# PADCFG_CTRL0_CFG0 register map
Vendor: Texas Instruments
Peripheral module from a debugger description file (folder am62A).
Registers are 32-bit, access per field, reset 0x8214007 unless marked. A register's access mark holds for its fields unless they carry their own. Offsets are as the file gives them; lines under a group give offsets from that group; [hi:lo] are bit positions; {n}, {i} and the like mark numbered series; 'fields as' and 'values as' point back to an identical list; <NAME> marks a mode.

## PADCFG_CTRL0_CFG0 (part 1 of 2)
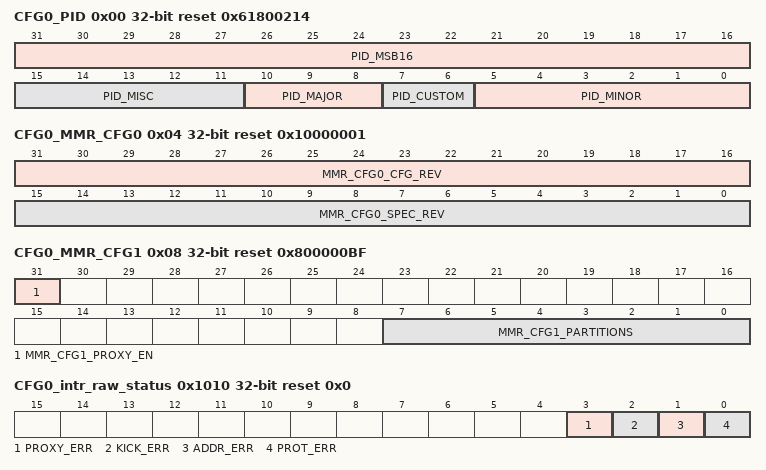
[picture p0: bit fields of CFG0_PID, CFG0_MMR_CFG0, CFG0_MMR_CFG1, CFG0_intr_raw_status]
0x00 CFG0_PID ro reset 0x61800214
  [31:16] PID_MSB16, [15:11] PID_MISC, [10:8] PID_MAJOR, [7:6] PID_CUSTOM, [5:0] PID_MINOR
0x04 CFG0_MMR_CFG0 ro reset 0x10000001
  [31:16] MMR_CFG0_CFG_REV — Major configuration release
  [15:0] MMR_CFG0_SPEC_REV — Minor spec-only revision. Doesn't change RTL release
0x08 CFG0_MMR_CFG1 ro reset 0x800000BF
  [31] MMR_CFG1_PROXY_EN — Proxy addressing enabled
  [7:0] MMR_CFG1_PARTITIONS — Indicates present partitions
0x1008 CFG0_LOCK0_KICK0 rw reset 0x0
  [31:0] LOCK0_KICK0 — - KICK0 component
0x100C CFG0_LOCK0_KICK1 rw reset 0x0
  [31:0] LOCK0_KICK1 — - KICK1 component
0x1010 CFG0_intr_raw_status access not given reset 0x0
  [3] PROXY_ERR — Proxy0 access violation error. Raw status is read. Write a 1 to set the status. Writing a 0 has no effect. (access R/W1TS)
  [2] KICK_ERR — Kick access violation error. Raw status is read. Write a 1 to set the status. Writing a 0 has no effect. (access R/W1TS)
  [1] ADDR_ERR — Addressing violation error. Raw status is read. Write a 1 to set the status. Writing a 0 has no effect. (access R/W1TS)
  [0] PROT_ERR — Protection violation error. Raw status is read. Write a 1 to set the status. Writing a 0 has no effect. (access R/W1TS)
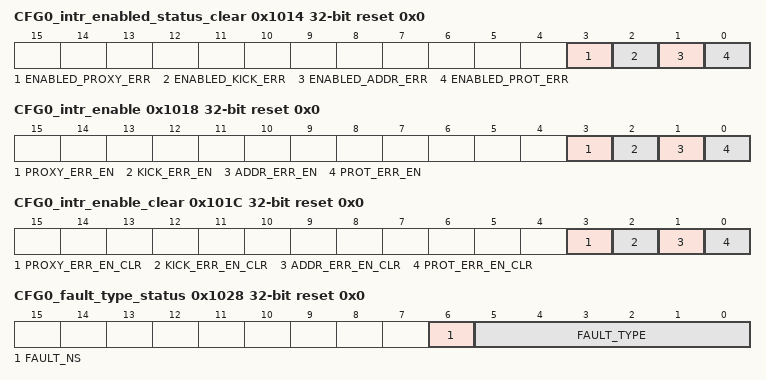
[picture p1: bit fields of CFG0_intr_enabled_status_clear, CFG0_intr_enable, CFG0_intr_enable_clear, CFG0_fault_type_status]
0x1014 CFG0_intr_enabled_status_clear access not given reset 0x0
  [3] ENABLED_PROXY_ERR — Proxy0 access violation error. Enabled status is read. Write a 1 to clear the status. Writing a 0 has no effect. (access R/W1TC)
  [2] ENABLED_KICK_ERR — Kick access violation error. Enabled status is read. Write a 1 to clear the status. Writing a 0 has no effect. (access R/W1TC)
  [1] ENABLED_ADDR_ERR — Addressing violation error. Enabled status is read. Write a 1 to clear the status. Writing a 0 has no effect. (access R/W1TC)
  [0] ENABLED_PROT_ERR — Protection violation error. Enabled status is read. Write a 1 to clear the status. Writing a 0 has no effect. (access R/W1TC)
0x1018 CFG0_intr_enable access not given reset 0x0
  [3] PROXY_ERR_EN — Proxy0 access violation error enable. Write a 1 to set the enable. Writing a 0 has no effect. (access R/W1TS)
  [2] KICK_ERR_EN — Kick access violation error enable. Write a 1 to set the enable. Writing a 0 has no effect. (access R/W1TS)
  [1] ADDR_ERR_EN — Addressing violation error enable. Write a 1 to set the enable. Writing a 0 has no effect. (access R/W1TS)
  [0] PROT_ERR_EN — Protection violation error enable. Write a 1 to set the enable. Writing a 0 has no effect. (access R/W1TS)
0x101C CFG0_intr_enable_clear access not given reset 0x0
  [3] PROXY_ERR_EN_CLR — Proxy0 access violation error enable clear. Write a 1 to clear the enable. Writing a 0 has no effect. (access R/W1TC)
  [2] KICK_ERR_EN_CLR — Kick access violation error enable clear. Write a 1 to clear the enable. Writing a 0 has no effect. (access R/W1TC)
  [1] ADDR_ERR_EN_CLR — Addressing violation error enable clear. Write a 1 to clear the enable. Writing a 0 has no effect. (access R/W1TC)
  [0] PROT_ERR_EN_CLR — Protection violation error enable clear. Write a 1 to clear the enable. Writing a 0 has no effect. (access R/W1TC)
0x1020 CFG0_eoi rw reset 0x0
  [7:0] EOI_VECTOR — EOI vector value. Write this with interrupt distribution value in the chip.
0x1024 CFG0_fault_address ro reset 0x0
  [31:0] FAULT_ADDR — Fault Address.
0x1028 CFG0_fault_type_status ro reset 0x0
  [6] FAULT_NS — Non-secure access.
  [5:0] FAULT_TYPE — Fault Type 10_0000 = Supervisor read fault - priv = 1 dir = 1 dtype != 1 01_0000 = Supervisor write fault - priv = 1 dir = 0 00_1000 = Supervisor execute fault - priv = 1 dir = 1 dtype = 1 00_0100 = User read fault - priv = 0 dir = 1 dtype = 1 00_0010 = User write fault - priv = 0 dir = 0 00_0001 = User execute fault - priv = 0 dir = 1 dtype = 1 00_0000 = No fault
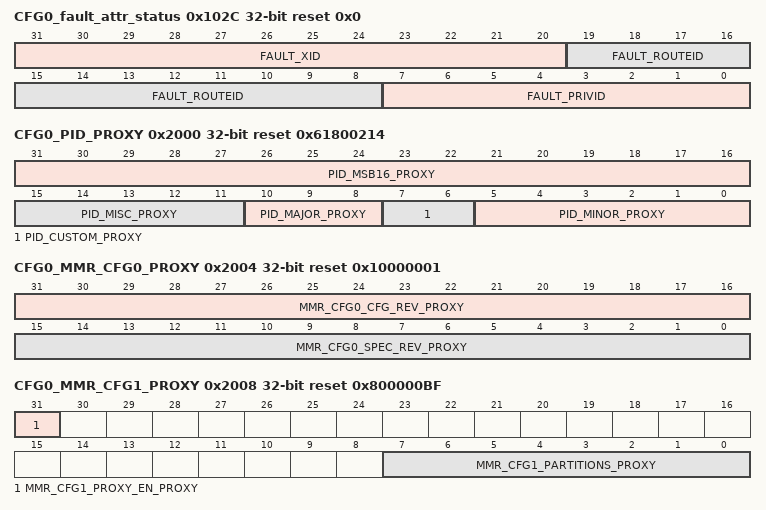
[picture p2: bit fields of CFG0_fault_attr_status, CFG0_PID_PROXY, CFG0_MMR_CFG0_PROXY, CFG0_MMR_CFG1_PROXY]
0x102C CFG0_fault_attr_status ro reset 0x0
  [31:20] FAULT_XID — XID.
  [19:8] FAULT_ROUTEID — Route ID.
  [7:0] FAULT_PRIVID — Privilege ID.
0x1030 CFG0_fault_clear wo reset 0x0
  [0] FAULT_CLR — Fault clear. Writing a 1 clears the current fault. Writing a 0 has no effect.
0x1100 CFG0_CLAIMREG_P0_R0_READONLY ro reset 0x0
  [31:0] CLAIMREG_P0_R0_READONLY — Claim bits for Partition 0
0x2000 CFG0_PID_PROXY ro reset 0x61800214
  [31:16] PID_MSB16_PROXY, [15:11] PID_MISC_PROXY, [10:8] PID_MAJOR_PROXY, [7:6] PID_CUSTOM_PROXY, [5:0] PID_MINOR_PROXY
0x2004 CFG0_MMR_CFG0_PROXY ro reset 0x10000001
  [31:16] MMR_CFG0_CFG_REV_PROXY — Major configuration release
  [15:0] MMR_CFG0_SPEC_REV_PROXY — Minor spec-only revision. Doesn't change RTL release
0x2008 CFG0_MMR_CFG1_PROXY ro reset 0x800000BF
  [31] MMR_CFG1_PROXY_EN_PROXY — Proxy addressing enabled
  [7:0] MMR_CFG1_PARTITIONS_PROXY — Indicates present partitions
0x3008 CFG0_LOCK0_KICK0_PROXY rw reset 0x0
  [31:0] LOCK0_KICK0_PROXY — - KICK0 component
0x300C CFG0_LOCK0_KICK1_PROXY rw reset 0x0
  [31:0] LOCK0_KICK1_PROXY — - KICK1 component
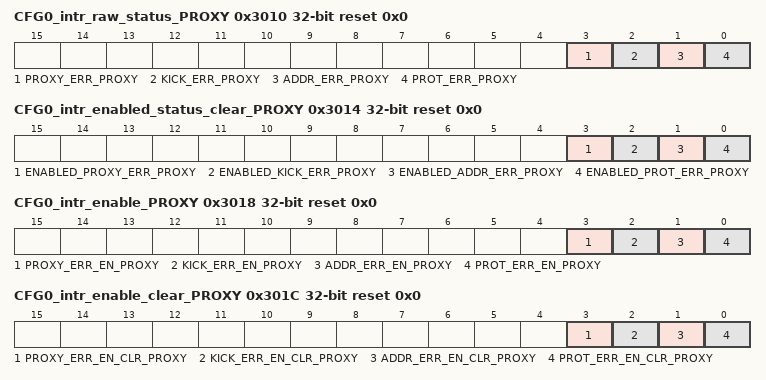
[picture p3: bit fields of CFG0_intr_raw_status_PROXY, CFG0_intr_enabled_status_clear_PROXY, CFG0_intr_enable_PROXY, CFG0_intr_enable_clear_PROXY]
0x3010 CFG0_intr_raw_status_PROXY access not given reset 0x0
  [3] PROXY_ERR_PROXY — Proxy0 access violation error. Raw status is read. Write a 1 to set the status. Writing a 0 has no effect. (access R/W1TS)
  [2] KICK_ERR_PROXY — Kick access violation error. Raw status is read. Write a 1 to set the status. Writing a 0 has no effect. (access R/W1TS)
  [1] ADDR_ERR_PROXY — Addressing violation error. Raw status is read. Write a 1 to set the status. Writing a 0 has no effect. (access R/W1TS)
  [0] PROT_ERR_PROXY — Protection violation error. Raw status is read. Write a 1 to set the status. Writing a 0 has no effect. (access R/W1TS)
0x3014 CFG0_intr_enabled_status_clear_PROXY access not given reset 0x0
  [3] ENABLED_PROXY_ERR_PROXY — Proxy0 access violation error. Enabled status is read. Write a 1 to clear the status. Writing a 0 has no effect. (access R/W1TC)
  [2] ENABLED_KICK_ERR_PROXY — Kick access violation error. Enabled status is read. Write a 1 to clear the status. Writing a 0 has no effect. (access R/W1TC)
  [1] ENABLED_ADDR_ERR_PROXY — Addressing violation error. Enabled status is read. Write a 1 to clear the status. Writing a 0 has no effect. (access R/W1TC)
  [0] ENABLED_PROT_ERR_PROXY — Protection violation error. Enabled status is read. Write a 1 to clear the status. Writing a 0 has no effect. (access R/W1TC)
0x3018 CFG0_intr_enable_PROXY access not given reset 0x0
  [3] PROXY_ERR_EN_PROXY — Proxy0 access violation error enable. Write a 1 to set the enable. Writing a 0 has no effect. (access R/W1TS)
  [2] KICK_ERR_EN_PROXY — Kick access violation error enable. Write a 1 to set the enable. Writing a 0 has no effect. (access R/W1TS)
  [1] ADDR_ERR_EN_PROXY — Addressing violation error enable. Write a 1 to set the enable. Writing a 0 has no effect. (access R/W1TS)
  [0] PROT_ERR_EN_PROXY — Protection violation error enable. Write a 1 to set the enable. Writing a 0 has no effect. (access R/W1TS)
0x301C CFG0_intr_enable_clear_PROXY access not given reset 0x0
  [3] PROXY_ERR_EN_CLR_PROXY — Proxy0 access violation error enable clear. Write a 1 to clear the enable. Writing a 0 has no effect. (access R/W1TC)
  [2] KICK_ERR_EN_CLR_PROXY — Kick access violation error enable clear. Write a 1 to clear the enable. Writing a 0 has no effect. (access R/W1TC)
  [1] ADDR_ERR_EN_CLR_PROXY — Addressing violation error enable clear. Write a 1 to clear the enable. Writing a 0 has no effect. (access R/W1TC)
  [0] PROT_ERR_EN_CLR_PROXY — Protection violation error enable clear. Write a 1 to clear the enable. Writing a 0 has no effect. (access R/W1TC)
0x3020 CFG0_eoi_PROXY rw reset 0x0
  [7:0] EOI_VECTOR_PROXY — EOI vector value. Write this with interrupt distribution value in the chip.
0x3024 CFG0_fault_address_PROXY ro reset 0x0
  [31:0] FAULT_ADDR_PROXY — Fault Address.
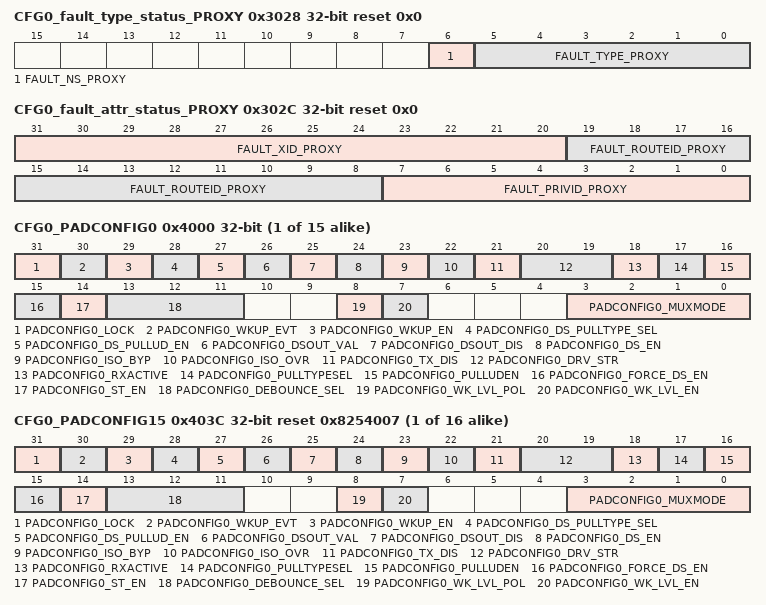
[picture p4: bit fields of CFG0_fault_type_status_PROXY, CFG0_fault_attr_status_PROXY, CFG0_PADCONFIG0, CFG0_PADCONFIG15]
0x3028 CFG0_fault_type_status_PROXY ro reset 0x0
  [6] FAULT_NS_PROXY — Non-secure access.
  [5:0] FAULT_TYPE_PROXY — Fault Type 10_0000 = Supervisor read fault - priv = 1 dir = 1 dtype != 1 01_0000 = Supervisor write fault - priv = 1 dir = 0 00_1000 = Supervisor execute fault - priv = 1 dir = 1 dtype = 1 00_0100 = User read fault - priv = 0 dir = 1 dtype = 1 00_0010 = User write fault - priv = 0 dir = 0 00_0001 = User execute fault - priv = 0 dir = 1 dtype = 1 00_0000 = No fault
0x302C CFG0_fault_attr_status_PROXY ro reset 0x0
  [31:20] FAULT_XID_PROXY — XID.
  [19:8] FAULT_ROUTEID_PROXY — Route ID.
  [7:0] FAULT_PRIVID_PROXY — Privilege ID.
0x3030 CFG0_fault_clear_PROXY wo reset 0x0
  [0] FAULT_CLR_PROXY — Fault clear. Writing a 1 clears the current fault. Writing a 0 has no effect.
0x3100 CFG0_CLAIMREG_P0_R0 rw reset 0x0
  [31:0] CLAIMREG_P0_R0 — Claim bits for Partition 0
{0x4000+4i} CFG0_PADCONFIG{i} (i=0..14)
  [31] PADCONFIG{i}_LOCK rw — Lock 0 - Padconfig register is unlocked 1 - Padconfig register is locked from further writes
  [30] PADCONFIG{i}_WKUP_EVT ro — Wakeup event status 0 - No wake event on pin 1 - Wake event occurred on pin
  [29] PADCONFIG{i}_WKUP_EN rw — Wakeup enable 0 - Wakeup operation disabled 1 - Wakeup operation enabled
  [28] PADCONFIG{i}_DS_PULLTYPE_SEL rw — Deep Sleep pull-up/down selection 0 - Offmode pulldown selected 1 - Offmode pullup selected
  [27] PADCONFIG{i}_DS_PULLUD_EN rw — Deep Sleep pull-up/down enable (active low) 0 - Pullup / pulldown is enabled 1 - Pullup / pulldown is disabled
  [26] PADCONFIG{i}_DSOUT_VAL rw — Deep Sleep output value 0 - Output value is 0 1 - Output value is 1
  [25] PADCONFIG{i}_DSOUT_DIS rw — Deep Sleep output disable 0 - Output enabled 1 - Output disabled
  [24] PADCONFIG{i}_DS_EN rw — Deep Sleep override control 0 - IO keeps its previous state when Deep Sleep mode is active 1 - IO state is forced to OFF mode value when Deep Sleep mode is active
  [23] PADCONFIG{i}_ISO_BYP rw — Isolation Bypass 0 - IO isolation is preserved 1 - IO isolation is bypassed
  [22] PADCONFIG{i}_ISO_OVR rw — Isolation Override 0 - IO isolation is preserved 1 - IO isolation is overridden
  [21] PADCONFIG{i}_TX_DIS rw — Driver Disable 0 - Driver is enabled 1 - Driver is disabled
  [20:19] PADCONFIG{i}_DRV_STR rw — Drive Strength Control . Selects the drive strength value for LVCMOS pins. (Does not apply to other pin types)
  [18] PADCONFIG{i}_RXACTIVE rw — Input enable for the Pad 0 - Receiver disabled 1 - Receiver enabled
  [17] PADCONFIG{i}_PULLTYPESEL rw — Pad Pullup / Pulldown type selection 0 - Pulldown selected 1 - Pullup selected
  [16] PADCONFIG{i}_PULLUDEN rw — Pad Pullup / Pulldown enable. This is an active low signal. 0 - Pullup / Pulldown enabled 1 - Pullup / Pulldown disabled
  [15] PADCONFIG{i}_FORCE_DS_EN rw — Enable pad Deep Sleep controls by overriding WKUP DM gating 0 - Deep Sleep pad controls are gated by the WKUP DM 1 - Activate Deep Sleep pad controls (override WKUP DM gating logic)
  [14] PADCONFIG{i}_ST_EN rw — Receiver Schmitt Trigger enable 0 - Schmitt trigger input disabled 1 - Schmitt trigger input enabled
  [13:11] PADCONFIG{i}_DEBOUNCE_SEL rw — Selects the debouce period for the pad.
  [8] PADCONFIG{i}_WK_LVL_POL rw — Level Sensitive Wakeup Polarity This bit is not relevant unless wk_lvl_en is set to 1'b1. 0 - Low. A low (0) value on the pin causes a wakeup 1 - High. A high (1) value on the pin causes a wakeup
  [7] PADCONFIG{i}_WK_LVL_EN rw — Level Sensitive Wakeup Enable 0 - Disabled. Wakeup is triggered by change of the pin input value 1 - Enabled. Wakeup is triggered when the pin matches the value specified by wk_lvl_pol. The chosen polarity must be maintained. (e.g. until wakeup completion is confirmed)
  [3:0] PADCONFIG{i}_MUXMODE rw — Pad functional signal mux selection Field values (others are reserved): 4'b0000 - Mux Mode 0 4'b0001 - Mux Mode 1 4'b0010 - Mux Mode 2 4'b0011 - Mux Mode 3 4'b0100 - Mux Mode 4 4'b0101 - Mux Mode 5 4'b0110 - Mux Mode 6 4'b0111 - Mux Mode 7 4'b1000 - Mux Mode 8 4'b1001 - Mux Mode 9 4'b1010 - Mux Mode 10 4'b1011 - Mux Mode 11 4'b1100 - Mux Mode 12 4'b1101 - Mux Mode 13 4'b1110 - Mux Mode 14 4'b1111 - Mux Mode 15
{0x4000+4i} CFG0_PADCONFIG{i} reset 0x8254007 (i=15..30)
  fields as CFG0_PADCONFIG0
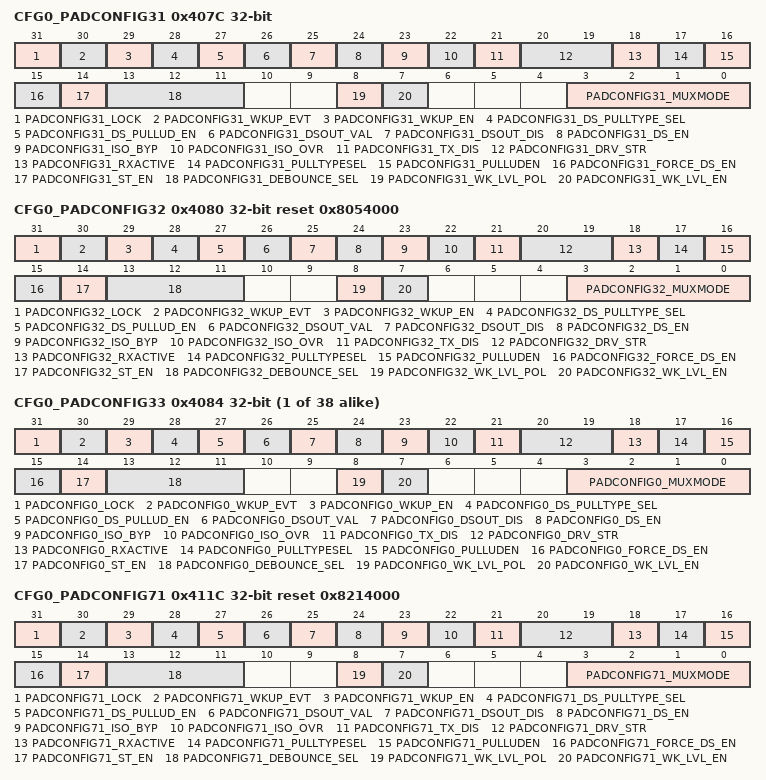
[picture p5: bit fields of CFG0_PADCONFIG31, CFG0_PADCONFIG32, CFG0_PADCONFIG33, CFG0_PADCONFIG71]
0x407C CFG0_PADCONFIG31
  [31] PADCONFIG31_LOCK rw — Lock 0 - Padconfig register is unlocked 1 - Padconfig register is locked from further writes
  [30] PADCONFIG31_WKUP_EVT ro — Wakeup event status 0 - No wake event on pin 1 - Wake event occurred on pin
  [29] PADCONFIG31_WKUP_EN rw — Wakeup enable 0 - Wakeup operation disabled 1 - Wakeup operation enabled
  [28] PADCONFIG31_DS_PULLTYPE_SEL rw — Deep Sleep pull-up/down selection 0 - Offmode pulldown selected 1 - Offmode pullup selected
  [27] PADCONFIG31_DS_PULLUD_EN rw — Deep Sleep pull-up/down enable (active low) 0 - Pullup / pulldown is enabled 1 - Pullup / pulldown is disabled
  [26] PADCONFIG31_DSOUT_VAL rw — Deep Sleep output value 0 - Output value is 0 1 - Output value is 1
  [25] PADCONFIG31_DSOUT_DIS rw — Deep Sleep output disable 0 - Output enabled 1 - Output disabled
  [24] PADCONFIG31_DS_EN rw — Deep Sleep override control 0 - IO keeps its previous state when Deep Sleep mode is active 1 - IO state is forced to OFF mode value when Deep Sleep mode is active
  [23] PADCONFIG31_ISO_BYP rw — Isolation Bypass 0 - IO isolation is preserved 1 - IO isolation is bypassed
  [22] PADCONFIG31_ISO_OVR rw — Isolation Override 0 - IO isolation is preserved 1 - IO isolation is overridden
  [21] PADCONFIG31_TX_DIS rw — Driver Disable 0 - Driver is enabled 1 - Driver is disabled
  [20:19] PADCONFIG31_DRV_STR rw — Drive Strength Control . Selects the drive strength value for LVCMOS pins. (Does not apply to other pin types)
  [18] PADCONFIG31_RXACTIVE rw — Input enable for the Pad 0 - Receiver disabled 1 - Receiver enabled
  [17] PADCONFIG31_PULLTYPESEL rw — Pad Pullup / Pulldown type selection 0 - Pulldown selected 1 - Pullup selected
  [16] PADCONFIG31_PULLUDEN rw — Pad Pullup / Pulldown enable. This is an active low signal. 0 - Pullup / Pulldown enabled 1 - Pullup / Pulldown disabled
  [15] PADCONFIG31_FORCE_DS_EN rw — Enable pad Deep Sleep controls by overriding WKUP DM gating 0 - Deep Sleep pad controls are gated by the WKUP DM 1 - Activate Deep Sleep pad controls (override WKUP DM gating logic)
  [14] PADCONFIG31_ST_EN rw — Receiver Schmitt Trigger enable 0 - Schmitt trigger input disabled 1 - Schmitt trigger input enabled
  [13:11] PADCONFIG31_DEBOUNCE_SEL rw — Selects the debouce period for the pad.
  [8] PADCONFIG31_WK_LVL_POL rw — Level Sensitive Wakeup Polarity This bit is not relevant unless wk_lvl_en is set to 1'b1. 0 - Low. A low (0) value on the pin causes a wakeup 1 - High. A high (1) value on the pin causes a wakeup
  [7] PADCONFIG31_WK_LVL_EN rw — Level Sensitive Wakeup Enable 0 - Disabled. Wakeup is triggered by change of the pin input value 1 - Enabled. Wakeup is triggered when the pin matches the value specified by wk_lvl_pol. The chosen polarity must be maintained. (e.g. until wakeup completion is confirmed)
  [3:0] PADCONFIG31_MUXMODE rw — Pad functional signal mux selection Field values (others are reserved): 4'b0000 - Mux Mode 0 4'b0001 - Mux Mode 1 4'b0010 - Mux Mode 2 4'b0011 - Mux Mode 3 4'b0100 - Mux Mode 4 4'b0101 - Mux Mode 5 4'b0110 - Mux Mode 6 4'b0111 - Mux Mode 7 4'b1000 - Mux Mode 8 4'b1001 - Mux Mode 9 4'b1010 - Mux Mode 10 4'b1011 - Mux Mode 11 4'b1100 - Mux Mode 12 4'b1101 - Mux Mode 13 4'b1110 - Mux Mode 14 4'b1111 - Mux Mode 15
0x4080 CFG0_PADCONFIG32 reset 0x8054000
  [31] PADCONFIG32_LOCK rw — Lock 0 - Padconfig register is unlocked 1 - Padconfig register is locked from further writes
  [30] PADCONFIG32_WKUP_EVT ro — Wakeup event status 0 - No wake event on pin 1 - Wake event occurred on pin
  [29] PADCONFIG32_WKUP_EN rw — Wakeup enable 0 - Wakeup operation disabled 1 - Wakeup operation enabled
  [28] PADCONFIG32_DS_PULLTYPE_SEL rw — Deep Sleep pull-up/down selection 0 - Offmode pulldown selected 1 - Offmode pullup selected
  [27] PADCONFIG32_DS_PULLUD_EN rw — Deep Sleep pull-up/down enable (active low) 0 - Pullup / pulldown is enabled 1 - Pullup / pulldown is disabled
  [26] PADCONFIG32_DSOUT_VAL rw — Deep Sleep output value 0 - Output value is 0 1 - Output value is 1
  [25] PADCONFIG32_DSOUT_DIS rw — Deep Sleep output disable 0 - Output enabled 1 - Output disabled
  [24] PADCONFIG32_DS_EN rw — Deep Sleep override control 0 - IO keeps its previous state when Deep Sleep mode is active 1 - IO state is forced to OFF mode value when Deep Sleep mode is active
  [23] PADCONFIG32_ISO_BYP rw — Isolation Bypass 0 - IO isolation is preserved 1 - IO isolation is bypassed
  [22] PADCONFIG32_ISO_OVR rw — Isolation Override 0 - IO isolation is preserved 1 - IO isolation is overridden
  [21] PADCONFIG32_TX_DIS rw — Driver Disable 0 - Driver is enabled 1 - Driver is disabled
  [20:19] PADCONFIG32_DRV_STR rw — Drive Strength Control . Selects the drive strength value for LVCMOS pins. (Does not apply to other pin types)
  [18] PADCONFIG32_RXACTIVE rw — Input enable for the Pad 0 - Receiver disabled 1 - Receiver enabled
  [17] PADCONFIG32_PULLTYPESEL rw — Pad Pullup / Pulldown type selection 0 - Pulldown selected 1 - Pullup selected
  [16] PADCONFIG32_PULLUDEN rw — Pad Pullup / Pulldown enable. This is an active low signal. 0 - Pullup / Pulldown enabled 1 - Pullup / Pulldown disabled
  [15] PADCONFIG32_FORCE_DS_EN rw — Enable pad Deep Sleep controls by overriding WKUP DM gating 0 - Deep Sleep pad controls are gated by the WKUP DM 1 - Activate Deep Sleep pad controls (override WKUP DM gating logic)
  [14] PADCONFIG32_ST_EN rw — Receiver Schmitt Trigger enable 0 - Schmitt trigger input disabled 1 - Schmitt trigger input enabled
  [13:11] PADCONFIG32_DEBOUNCE_SEL rw — Selects the debouce period for the pad.
  [8] PADCONFIG32_WK_LVL_POL rw — Level Sensitive Wakeup Polarity This bit is not relevant unless wk_lvl_en is set to 1'b1. 0 - Low. A low (0) value on the pin causes a wakeup 1 - High. A high (1) value on the pin causes a wakeup
  [7] PADCONFIG32_WK_LVL_EN rw — Level Sensitive Wakeup Enable 0 - Disabled. Wakeup is triggered by change of the pin input value 1 - Enabled. Wakeup is triggered when the pin matches the value specified by wk_lvl_pol. The chosen polarity must be maintained. (e.g. until wakeup completion is confirmed)
  [3:0] PADCONFIG32_MUXMODE rw — Pad functional signal mux selection Field values (others are reserved): 4'b0000 - Mux Mode 0 4'b0001 - Mux Mode 1 4'b0010 - Mux Mode 2 4'b0011 - Mux Mode 3 4'b0100 - Mux Mode 4 4'b0101 - Mux Mode 5 4'b0110 - Mux Mode 6 4'b0111 - Mux Mode 7 4'b1000 - Mux Mode 8 4'b1001 - Mux Mode 9 4'b1010 - Mux Mode 10 4'b1011 - Mux Mode 11 4'b1100 - Mux Mode 12 4'b1101 - Mux Mode 13 4'b1110 - Mux Mode 14 4'b1111 - Mux Mode 15
{0x4000+4i} CFG0_PADCONFIG{i} (i=33..70)
  fields as CFG0_PADCONFIG0
0x411C CFG0_PADCONFIG71 reset 0x8214000
  [31] PADCONFIG71_LOCK rw — Lock 0 - Padconfig register is unlocked 1 - Padconfig register is locked from further writes
  [30] PADCONFIG71_WKUP_EVT ro — Wakeup event status 0 - No wake event on pin 1 - Wake event occurred on pin
  [29] PADCONFIG71_WKUP_EN rw — Wakeup enable 0 - Wakeup operation disabled 1 - Wakeup operation enabled
  [28] PADCONFIG71_DS_PULLTYPE_SEL rw — Deep Sleep pull-up/down selection 0 - Offmode pulldown selected 1 - Offmode pullup selected
  [27] PADCONFIG71_DS_PULLUD_EN rw — Deep Sleep pull-up/down enable (active low) 0 - Pullup / pulldown is enabled 1 - Pullup / pulldown is disabled
  [26] PADCONFIG71_DSOUT_VAL rw — Deep Sleep output value 0 - Output value is 0 1 - Output value is 1
  [25] PADCONFIG71_DSOUT_DIS rw — Deep Sleep output disable 0 - Output enabled 1 - Output disabled
  [24] PADCONFIG71_DS_EN rw — Deep Sleep override control 0 - IO keeps its previous state when Deep Sleep mode is active 1 - IO state is forced to OFF mode value when Deep Sleep mode is active
  [23] PADCONFIG71_ISO_BYP rw — Isolation Bypass 0 - IO isolation is preserved 1 - IO isolation is bypassed
  [22] PADCONFIG71_ISO_OVR rw — Isolation Override 0 - IO isolation is preserved 1 - IO isolation is overridden
  [21] PADCONFIG71_TX_DIS rw — Driver Disable 0 - Driver is enabled 1 - Driver is disabled
  [20:19] PADCONFIG71_DRV_STR rw — Drive Strength Control . Selects the drive strength value for LVCMOS pins. (Does not apply to other pin types)
  [18] PADCONFIG71_RXACTIVE rw — Input enable for the Pad 0 - Receiver disabled 1 - Receiver enabled
  [17] PADCONFIG71_PULLTYPESEL rw — Pad Pullup / Pulldown type selection 0 - Pulldown selected 1 - Pullup selected
  [16] PADCONFIG71_PULLUDEN rw — Pad Pullup / Pulldown enable. This is an active low signal. 0 - Pullup / Pulldown enabled 1 - Pullup / Pulldown disabled
  [15] PADCONFIG71_FORCE_DS_EN rw — Enable pad Deep Sleep controls by overriding WKUP DM gating 0 - Deep Sleep pad controls are gated by the WKUP DM 1 - Activate Deep Sleep pad controls (override WKUP DM gating logic)
  [14] PADCONFIG71_ST_EN rw — Receiver Schmitt Trigger enable 0 - Schmitt trigger input disabled 1 - Schmitt trigger input enabled
  [13:11] PADCONFIG71_DEBOUNCE_SEL rw — Selects the debouce period for the pad.
  [8] PADCONFIG71_WK_LVL_POL rw — Level Sensitive Wakeup Polarity This bit is not relevant unless wk_lvl_en is set to 1'b1. 0 - Low. A low (0) value on the pin causes a wakeup 1 - High. A high (1) value on the pin causes a wakeup
  [7] PADCONFIG71_WK_LVL_EN rw — Level Sensitive Wakeup Enable 0 - Disabled. Wakeup is triggered by change of the pin input value 1 - Enabled. Wakeup is triggered when the pin matches the value specified by wk_lvl_pol. The chosen polarity must be maintained. (e.g. until wakeup completion is confirmed)
  [3:0] PADCONFIG71_MUXMODE rw — Pad functional signal mux selection Field values (others are reserved): 4'b0000 - Mux Mode 0 4'b0001 - Mux Mode 1 4'b0010 - Mux Mode 2 4'b0011 - Mux Mode 3 4'b0100 - Mux Mode 4 4'b0101 - Mux Mode 5 4'b0110 - Mux Mode 6 4'b0111 - Mux Mode 7 4'b1000 - Mux Mode 8 4'b1001 - Mux Mode 9 4'b1010 - Mux Mode 10 4'b1011 - Mux Mode 11 4'b1100 - Mux Mode 12 4'b1101 - Mux Mode 13 4'b1110 - Mux Mode 14 4'b1111 - Mux Mode 15
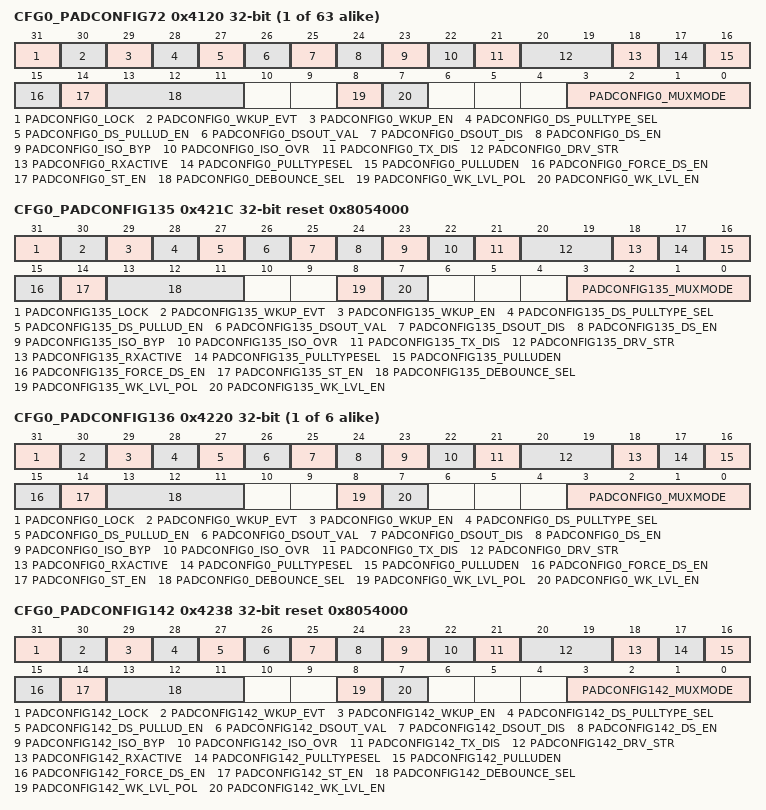
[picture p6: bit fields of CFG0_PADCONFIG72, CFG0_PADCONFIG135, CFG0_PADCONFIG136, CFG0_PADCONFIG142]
{0x4000+4i} CFG0_PADCONFIG{i} (i=72..134)
  fields as CFG0_PADCONFIG0
0x421C CFG0_PADCONFIG135 reset 0x8054000
  [31] PADCONFIG135_LOCK rw — Lock 0 - Padconfig register is unlocked 1 - Padconfig register is locked from further writes
  [30] PADCONFIG135_WKUP_EVT ro — Wakeup event status 0 - No wake event on pin 1 - Wake event occurred on pin
  [29] PADCONFIG135_WKUP_EN rw — Wakeup enable 0 - Wakeup operation disabled 1 - Wakeup operation enabled
  [28] PADCONFIG135_DS_PULLTYPE_SEL rw — Deep Sleep pull-up/down selection 0 - Offmode pulldown selected 1 - Offmode pullup selected
  [27] PADCONFIG135_DS_PULLUD_EN rw — Deep Sleep pull-up/down enable (active low) 0 - Pullup / pulldown is enabled 1 - Pullup / pulldown is disabled
  [26] PADCONFIG135_DSOUT_VAL rw — Deep Sleep output value 0 - Output value is 0 1 - Output value is 1
  [25] PADCONFIG135_DSOUT_DIS rw — Deep Sleep output disable 0 - Output enabled 1 - Output disabled
  [24] PADCONFIG135_DS_EN rw — Deep Sleep override control 0 - IO keeps its previous state when Deep Sleep mode is active 1 - IO state is forced to OFF mode value when Deep Sleep mode is active
  [23] PADCONFIG135_ISO_BYP rw — Isolation Bypass 0 - IO isolation is preserved 1 - IO isolation is bypassed
  [22] PADCONFIG135_ISO_OVR rw — Isolation Override 0 - IO isolation is preserved 1 - IO isolation is overridden
  [21] PADCONFIG135_TX_DIS rw — Driver Disable 0 - Driver is enabled 1 - Driver is disabled
  [20:19] PADCONFIG135_DRV_STR rw — Drive Strength Control . Selects the drive strength value for LVCMOS pins. (Does not apply to other pin types)
  [18] PADCONFIG135_RXACTIVE rw — Input enable for the Pad 0 - Receiver disabled 1 - Receiver enabled
  [17] PADCONFIG135_PULLTYPESEL rw — Pad Pullup / Pulldown type selection 0 - Pulldown selected 1 - Pullup selected
  [16] PADCONFIG135_PULLUDEN rw — Pad Pullup / Pulldown enable. This is an active low signal. 0 - Pullup / Pulldown enabled 1 - Pullup / Pulldown disabled
  [15] PADCONFIG135_FORCE_DS_EN rw — Enable pad Deep Sleep controls by overriding WKUP DM gating 0 - Deep Sleep pad controls are gated by the WKUP DM 1 - Activate Deep Sleep pad controls (override WKUP DM gating logic)
  [14] PADCONFIG135_ST_EN rw — Receiver Schmitt Trigger enable 0 - Schmitt trigger input disabled 1 - Schmitt trigger input enabled
  [13:11] PADCONFIG135_DEBOUNCE_SEL rw — Selects the debouce period for the pad.
  [8] PADCONFIG135_WK_LVL_POL rw — Level Sensitive Wakeup Polarity This bit is not relevant unless wk_lvl_en is set to 1'b1. 0 - Low. A low (0) value on the pin causes a wakeup 1 - High. A high (1) value on the pin causes a wakeup
  [7] PADCONFIG135_WK_LVL_EN rw — Level Sensitive Wakeup Enable 0 - Disabled. Wakeup is triggered by change of the pin input value 1 - Enabled. Wakeup is triggered when the pin matches the value specified by wk_lvl_pol. The chosen polarity must be maintained. (e.g. until wakeup completion is confirmed)
  [3:0] PADCONFIG135_MUXMODE rw — Pad functional signal mux selection Field values (others are reserved): 4'b0000 - Mux Mode 0 4'b0001 - Mux Mode 1 4'b0010 - Mux Mode 2 4'b0011 - Mux Mode 3 4'b0100 - Mux Mode 4 4'b0101 - Mux Mode 5 4'b0110 - Mux Mode 6 4'b0111 - Mux Mode 7 4'b1000 - Mux Mode 8 4'b1001 - Mux Mode 9 4'b1010 - Mux Mode 10 4'b1011 - Mux Mode 11 4'b1100 - Mux Mode 12 4'b1101 - Mux Mode 13 4'b1110 - Mux Mode 14 4'b1111 - Mux Mode 15
{0x4000+4i} CFG0_PADCONFIG{i} (i=136..141)
  fields as CFG0_PADCONFIG0
0x4238 CFG0_PADCONFIG142 reset 0x8054000
  [31] PADCONFIG142_LOCK rw — Lock 0 - Padconfig register is unlocked 1 - Padconfig register is locked from further writes
  [30] PADCONFIG142_WKUP_EVT ro — Wakeup event status 0 - No wake event on pin 1 - Wake event occurred on pin
  [29] PADCONFIG142_WKUP_EN rw — Wakeup enable 0 - Wakeup operation disabled 1 - Wakeup operation enabled
  [28] PADCONFIG142_DS_PULLTYPE_SEL rw — Deep Sleep pull-up/down selection 0 - Offmode pulldown selected 1 - Offmode pullup selected
  [27] PADCONFIG142_DS_PULLUD_EN rw — Deep Sleep pull-up/down enable (active low) 0 - Pullup / pulldown is enabled 1 - Pullup / pulldown is disabled
  [26] PADCONFIG142_DSOUT_VAL rw — Deep Sleep output value 0 - Output value is 0 1 - Output value is 1
  [25] PADCONFIG142_DSOUT_DIS rw — Deep Sleep output disable 0 - Output enabled 1 - Output disabled
  [24] PADCONFIG142_DS_EN rw — Deep Sleep override control 0 - IO keeps its previous state when Deep Sleep mode is active 1 - IO state is forced to OFF mode value when Deep Sleep mode is active
  [23] PADCONFIG142_ISO_BYP rw — Isolation Bypass 0 - IO isolation is preserved 1 - IO isolation is bypassed
  [22] PADCONFIG142_ISO_OVR rw — Isolation Override 0 - IO isolation is preserved 1 - IO isolation is overridden
  [21] PADCONFIG142_TX_DIS rw — Driver Disable 0 - Driver is enabled 1 - Driver is disabled
  [20:19] PADCONFIG142_DRV_STR rw — Drive Strength Control . Selects the drive strength value for LVCMOS pins. (Does not apply to other pin types)
  [18] PADCONFIG142_RXACTIVE rw — Input enable for the Pad 0 - Receiver disabled 1 - Receiver enabled
  [17] PADCONFIG142_PULLTYPESEL rw — Pad Pullup / Pulldown type selection 0 - Pulldown selected 1 - Pullup selected
  [16] PADCONFIG142_PULLUDEN rw — Pad Pullup / Pulldown enable. This is an active low signal. 0 - Pullup / Pulldown enabled 1 - Pullup / Pulldown disabled
  [15] PADCONFIG142_FORCE_DS_EN rw — Enable pad Deep Sleep controls by overriding WKUP DM gating 0 - Deep Sleep pad controls are gated by the WKUP DM 1 - Activate Deep Sleep pad controls (override WKUP DM gating logic)
  [14] PADCONFIG142_ST_EN rw — Receiver Schmitt Trigger enable 0 - Schmitt trigger input disabled 1 - Schmitt trigger input enabled
  [13:11] PADCONFIG142_DEBOUNCE_SEL rw — Selects the debouce period for the pad.
  [8] PADCONFIG142_WK_LVL_POL rw — Level Sensitive Wakeup Polarity This bit is not relevant unless wk_lvl_en is set to 1'b1. 0 - Low. A low (0) value on the pin causes a wakeup 1 - High. A high (1) value on the pin causes a wakeup
  [7] PADCONFIG142_WK_LVL_EN rw — Level Sensitive Wakeup Enable 0 - Disabled. Wakeup is triggered by change of the pin input value 1 - Enabled. Wakeup is triggered when the pin matches the value specified by wk_lvl_pol. The chosen polarity must be maintained. (e.g. until wakeup completion is confirmed)
  [3:0] PADCONFIG142_MUXMODE rw — Pad functional signal mux selection Field values (others are reserved): 4'b0000 - Mux Mode 0 4'b0001 - Mux Mode 1 4'b0010 - Mux Mode 2 4'b0011 - Mux Mode 3 4'b0100 - Mux Mode 4 4'b0101 - Mux Mode 5 4'b0110 - Mux Mode 6 4'b0111 - Mux Mode 7 4'b1000 - Mux Mode 8 4'b1001 - Mux Mode 9 4'b1010 - Mux Mode 10 4'b1011 - Mux Mode 11 4'b1100 - Mux Mode 12 4'b1101 - Mux Mode 13 4'b1110 - Mux Mode 14 4'b1111 - Mux Mode 15
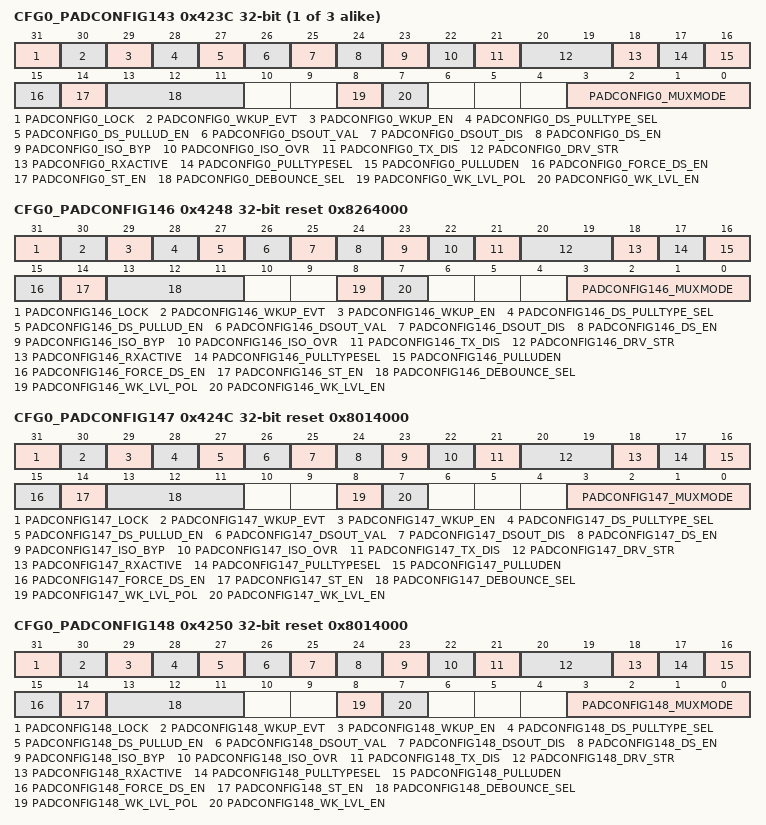
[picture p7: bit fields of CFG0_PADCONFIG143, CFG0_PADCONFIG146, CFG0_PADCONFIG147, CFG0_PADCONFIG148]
{0x4000+4i} CFG0_PADCONFIG{i} (i=143..145)
  fields as CFG0_PADCONFIG0
0x4248 CFG0_PADCONFIG146 reset 0x8264000
  [31] PADCONFIG146_LOCK rw — Lock 0 - Padconfig register is unlocked 1 - Padconfig register is locked from further writes
  [30] PADCONFIG146_WKUP_EVT ro — Wakeup event status 0 - No wake event on pin 1 - Wake event occurred on pin
  [29] PADCONFIG146_WKUP_EN rw — Wakeup enable 0 - Wakeup operation disabled 1 - Wakeup operation enabled
  [28] PADCONFIG146_DS_PULLTYPE_SEL rw — Deep Sleep pull-up/down selection 0 - Offmode pulldown selected 1 - Offmode pullup selected
  [27] PADCONFIG146_DS_PULLUD_EN rw — Deep Sleep pull-up/down enable (active low) 0 - Pullup / pulldown is enabled 1 - Pullup / pulldown is disabled
  [26] PADCONFIG146_DSOUT_VAL rw — Deep Sleep output value 0 - Output value is 0 1 - Output value is 1
  [25] PADCONFIG146_DSOUT_DIS rw — Deep Sleep output disable 0 - Output enabled 1 - Output disabled
  [24] PADCONFIG146_DS_EN rw — Deep Sleep override control 0 - IO keeps its previous state when Deep Sleep mode is active 1 - IO state is forced to OFF mode value when Deep Sleep mode is active
  [23] PADCONFIG146_ISO_BYP rw — Isolation Bypass 0 - IO isolation is preserved 1 - IO isolation is bypassed
  [22] PADCONFIG146_ISO_OVR rw — Isolation Override 0 - IO isolation is preserved 1 - IO isolation is overridden
  [21] PADCONFIG146_TX_DIS rw — Driver Disable 0 - Driver is enabled 1 - Driver is disabled
  [20:19] PADCONFIG146_DRV_STR rw — Drive Strength Control . Selects the drive strength value for LVCMOS pins. (Does not apply to other pin types)
  [18] PADCONFIG146_RXACTIVE rw — Input enable for the Pad 0 - Receiver disabled 1 - Receiver enabled
  [17] PADCONFIG146_PULLTYPESEL rw — Pad Pullup / Pulldown type selection 0 - Pulldown selected 1 - Pullup selected
  [16] PADCONFIG146_PULLUDEN rw — Pad Pullup / Pulldown enable. This is an active low signal. 0 - Pullup / Pulldown enabled 1 - Pullup / Pulldown disabled
  [15] PADCONFIG146_FORCE_DS_EN rw — Enable pad Deep Sleep controls by overriding WKUP DM gating 0 - Deep Sleep pad controls are gated by the WKUP DM 1 - Activate Deep Sleep pad controls (override WKUP DM gating logic)
  [14] PADCONFIG146_ST_EN rw — Receiver Schmitt Trigger enable 0 - Schmitt trigger input disabled 1 - Schmitt trigger input enabled
  [13:11] PADCONFIG146_DEBOUNCE_SEL rw — Selects the debouce period for the pad.
  [8] PADCONFIG146_WK_LVL_POL rw — Level Sensitive Wakeup Polarity This bit is not relevant unless wk_lvl_en is set to 1'b1. 0 - Low. A low (0) value on the pin causes a wakeup 1 - High. A high (1) value on the pin causes a wakeup
  [7] PADCONFIG146_WK_LVL_EN rw — Level Sensitive Wakeup Enable 0 - Disabled. Wakeup is triggered by change of the pin input value 1 - Enabled. Wakeup is triggered when the pin matches the value specified by wk_lvl_pol. The chosen polarity must be maintained. (e.g. until wakeup completion is confirmed)
  [3:0] PADCONFIG146_MUXMODE rw — Pad functional signal mux selection Field values (others are reserved): 4'b0000 - Mux Mode 0 4'b0001 - Mux Mode 1 4'b0010 - Mux Mode 2 4'b0011 - Mux Mode 3 4'b0100 - Mux Mode 4 4'b0101 - Mux Mode 5 4'b0110 - Mux Mode 6 4'b0111 - Mux Mode 7 4'b1000 - Mux Mode 8 4'b1001 - Mux Mode 9 4'b1010 - Mux Mode 10 4'b1011 - Mux Mode 11 4'b1100 - Mux Mode 12 4'b1101 - Mux Mode 13 4'b1110 - Mux Mode 14 4'b1111 - Mux Mode 15
0x424C CFG0_PADCONFIG147 reset 0x8014000
  [31] PADCONFIG147_LOCK rw — Lock 0 - Padconfig register is unlocked 1 - Padconfig register is locked from further writes
  [30] PADCONFIG147_WKUP_EVT ro — Wakeup event status 0 - No wake event on pin 1 - Wake event occurred on pin
  [29] PADCONFIG147_WKUP_EN rw — Wakeup enable 0 - Wakeup operation disabled 1 - Wakeup operation enabled
  [28] PADCONFIG147_DS_PULLTYPE_SEL rw — Deep Sleep pull-up/down selection 0 - Offmode pulldown selected 1 - Offmode pullup selected
  [27] PADCONFIG147_DS_PULLUD_EN rw — Deep Sleep pull-up/down enable (active low) 0 - Pullup / pulldown is enabled 1 - Pullup / pulldown is disabled
  [26] PADCONFIG147_DSOUT_VAL rw — Deep Sleep output value 0 - Output value is 0 1 - Output value is 1
  [25] PADCONFIG147_DSOUT_DIS rw — Deep Sleep output disable 0 - Output enabled 1 - Output disabled
  [24] PADCONFIG147_DS_EN rw — Deep Sleep override control 0 - IO keeps its previous state when Deep Sleep mode is active 1 - IO state is forced to OFF mode value when Deep Sleep mode is active
  [23] PADCONFIG147_ISO_BYP rw — Isolation Bypass 0 - IO isolation is preserved 1 - IO isolation is bypassed
  [22] PADCONFIG147_ISO_OVR rw — Isolation Override 0 - IO isolation is preserved 1 - IO isolation is overridden
  [21] PADCONFIG147_TX_DIS rw — Driver Disable 0 - Driver is enabled 1 - Driver is disabled
  [20:19] PADCONFIG147_DRV_STR rw — Drive Strength Control . Selects the drive strength value for LVCMOS pins. (Does not apply to other pin types)
  [18] PADCONFIG147_RXACTIVE rw — Input enable for the Pad 0 - Receiver disabled 1 - Receiver enabled
  [17] PADCONFIG147_PULLTYPESEL rw — Pad Pullup / Pulldown type selection 0 - Pulldown selected 1 - Pullup selected
  [16] PADCONFIG147_PULLUDEN rw — Pad Pullup / Pulldown enable. This is an active low signal. 0 - Pullup / Pulldown enabled 1 - Pullup / Pulldown disabled
  [15] PADCONFIG147_FORCE_DS_EN rw — Enable pad Deep Sleep controls by overriding WKUP DM gating 0 - Deep Sleep pad controls are gated by the WKUP DM 1 - Activate Deep Sleep pad controls (override WKUP DM gating logic)
  [14] PADCONFIG147_ST_EN rw — Receiver Schmitt Trigger enable 0 - Schmitt trigger input disabled 1 - Schmitt trigger input enabled
  [13:11] PADCONFIG147_DEBOUNCE_SEL rw — Selects the debouce period for the pad.
  [8] PADCONFIG147_WK_LVL_POL rw — Level Sensitive Wakeup Polarity This bit is not relevant unless wk_lvl_en is set to 1'b1. 0 - Low. A low (0) value on the pin causes a wakeup 1 - High. A high (1) value on the pin causes a wakeup
  [7] PADCONFIG147_WK_LVL_EN rw — Level Sensitive Wakeup Enable 0 - Disabled. Wakeup is triggered by change of the pin input value 1 - Enabled. Wakeup is triggered when the pin matches the value specified by wk_lvl_pol. The chosen polarity must be maintained. (e.g. until wakeup completion is confirmed)
  [3:0] PADCONFIG147_MUXMODE rw — Pad functional signal mux selection Field values (others are reserved): 4'b0000 - Mux Mode 0 4'b0001 - Mux Mode 1 4'b0010 - Mux Mode 2 4'b0011 - Mux Mode 3 4'b0100 - Mux Mode 4 4'b0101 - Mux Mode 5 4'b0110 - Mux Mode 6 4'b0111 - Mux Mode 7 4'b1000 - Mux Mode 8 4'b1001 - Mux Mode 9 4'b1010 - Mux Mode 10 4'b1011 - Mux Mode 11 4'b1100 - Mux Mode 12 4'b1101 - Mux Mode 13 4'b1110 - Mux Mode 14 4'b1111 - Mux Mode 15
0x4250 CFG0_PADCONFIG148 reset 0x8014000
  [31] PADCONFIG148_LOCK rw — Lock 0 - Padconfig register is unlocked 1 - Padconfig register is locked from further writes
  [30] PADCONFIG148_WKUP_EVT ro — Wakeup event status 0 - No wake event on pin 1 - Wake event occurred on pin
  [29] PADCONFIG148_WKUP_EN rw — Wakeup enable 0 - Wakeup operation disabled 1 - Wakeup operation enabled
  [28] PADCONFIG148_DS_PULLTYPE_SEL rw — Deep Sleep pull-up/down selection 0 - Offmode pulldown selected 1 - Offmode pullup selected
  [27] PADCONFIG148_DS_PULLUD_EN rw — Deep Sleep pull-up/down enable (active low) 0 - Pullup / pulldown is enabled 1 - Pullup / pulldown is disabled
  [26] PADCONFIG148_DSOUT_VAL rw — Deep Sleep output value 0 - Output value is 0 1 - Output value is 1
  [25] PADCONFIG148_DSOUT_DIS rw — Deep Sleep output disable 0 - Output enabled 1 - Output disabled
  [24] PADCONFIG148_DS_EN rw — Deep Sleep override control 0 - IO keeps its previous state when Deep Sleep mode is active 1 - IO state is forced to OFF mode value when Deep Sleep mode is active
  [23] PADCONFIG148_ISO_BYP rw — Isolation Bypass 0 - IO isolation is preserved 1 - IO isolation is bypassed
  [22] PADCONFIG148_ISO_OVR rw — Isolation Override 0 - IO isolation is preserved 1 - IO isolation is overridden
  [21] PADCONFIG148_TX_DIS rw — Driver Disable 0 - Driver is enabled 1 - Driver is disabled
  [20:19] PADCONFIG148_DRV_STR rw — Drive Strength Control . Selects the drive strength value for LVCMOS pins. (Does not apply to other pin types)
  [18] PADCONFIG148_RXACTIVE rw — Input enable for the Pad 0 - Receiver disabled 1 - Receiver enabled
  [17] PADCONFIG148_PULLTYPESEL rw — Pad Pullup / Pulldown type selection 0 - Pulldown selected 1 - Pullup selected
  [16] PADCONFIG148_PULLUDEN rw — Pad Pullup / Pulldown enable. This is an active low signal. 0 - Pullup / Pulldown enabled 1 - Pullup / Pulldown disabled
  [15] PADCONFIG148_FORCE_DS_EN rw — Enable pad Deep Sleep controls by overriding WKUP DM gating 0 - Deep Sleep pad controls are gated by the WKUP DM 1 - Activate Deep Sleep pad controls (override WKUP DM gating logic)
  [14] PADCONFIG148_ST_EN rw — Receiver Schmitt Trigger enable 0 - Schmitt trigger input disabled 1 - Schmitt trigger input enabled
  [13:11] PADCONFIG148_DEBOUNCE_SEL rw — Selects the debouce period for the pad.
  [8] PADCONFIG148_WK_LVL_POL rw — Level Sensitive Wakeup Polarity This bit is not relevant unless wk_lvl_en is set to 1'b1. 0 - Low. A low (0) value on the pin causes a wakeup 1 - High. A high (1) value on the pin causes a wakeup
  [7] PADCONFIG148_WK_LVL_EN rw — Level Sensitive Wakeup Enable 0 - Disabled. Wakeup is triggered by change of the pin input value 1 - Enabled. Wakeup is triggered when the pin matches the value specified by wk_lvl_pol. The chosen polarity must be maintained. (e.g. until wakeup completion is confirmed)
  [3:0] PADCONFIG148_MUXMODE rw — Pad functional signal mux selection Field values (others are reserved): 4'b0000 - Mux Mode 0 4'b0001 - Mux Mode 1 4'b0010 - Mux Mode 2 4'b0011 - Mux Mode 3 4'b0100 - Mux Mode 4 4'b0101 - Mux Mode 5 4'b0110 - Mux Mode 6 4'b0111 - Mux Mode 7 4'b1000 - Mux Mode 8 4'b1001 - Mux Mode 9 4'b1010 - Mux Mode 10 4'b1011 - Mux Mode 11 4'b1100 - Mux Mode 12 4'b1101 - Mux Mode 13 4'b1110 - Mux Mode 14 4'b1111 - Mux Mode 15
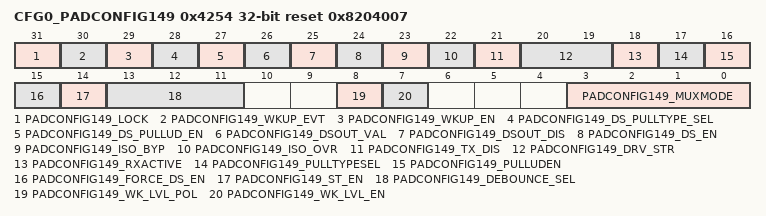
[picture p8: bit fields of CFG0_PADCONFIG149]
0x4254 CFG0_PADCONFIG149 reset 0x8204007
  [31] PADCONFIG149_LOCK rw — Lock 0 - Padconfig register is unlocked 1 - Padconfig register is locked from further writes
  [30] PADCONFIG149_WKUP_EVT ro — Wakeup event status 0 - No wake event on pin 1 - Wake event occurred on pin
  [29] PADCONFIG149_WKUP_EN rw — Wakeup enable 0 - Wakeup operation disabled 1 - Wakeup operation enabled
  [28] PADCONFIG149_DS_PULLTYPE_SEL rw — Deep Sleep pull-up/down selection 0 - Offmode pulldown selected 1 - Offmode pullup selected
  [27] PADCONFIG149_DS_PULLUD_EN rw — Deep Sleep pull-up/down enable (active low) 0 - Pullup / pulldown is enabled 1 - Pullup / pulldown is disabled
  [26] PADCONFIG149_DSOUT_VAL rw — Deep Sleep output value 0 - Output value is 0 1 - Output value is 1
  [25] PADCONFIG149_DSOUT_DIS rw — Deep Sleep output disable 0 - Output enabled 1 - Output disabled
  [24] PADCONFIG149_DS_EN rw — Deep Sleep override control 0 - IO keeps its previous state when Deep Sleep mode is active 1 - IO state is forced to OFF mode value when Deep Sleep mode is active
  [23] PADCONFIG149_ISO_BYP rw — Isolation Bypass 0 - IO isolation is preserved 1 - IO isolation is bypassed
  [22] PADCONFIG149_ISO_OVR rw — Isolation Override 0 - IO isolation is preserved 1 - IO isolation is overridden
  [21] PADCONFIG149_TX_DIS rw — Driver Disable 0 - Driver is enabled 1 - Driver is disabled
  [20:19] PADCONFIG149_DRV_STR rw — Drive Strength Control . Selects the drive strength value for LVCMOS pins. (Does not apply to other pin types)
  [18] PADCONFIG149_RXACTIVE rw — Input enable for the Pad 0 - Receiver disabled 1 - Receiver enabled
  [17] PADCONFIG149_PULLTYPESEL rw — Pad Pullup / Pulldown type selection 0 - Pulldown selected 1 - Pullup selected
  [16] PADCONFIG149_PULLUDEN rw — Pad Pullup / Pulldown enable. This is an active low signal. 0 - Pullup / Pulldown enabled 1 - Pullup / Pulldown disabled
  [15] PADCONFIG149_FORCE_DS_EN rw — Enable pad Deep Sleep controls by overriding WKUP DM gating 0 - Deep Sleep pad controls are gated by the WKUP DM 1 - Activate Deep Sleep pad controls (override WKUP DM gating logic)
  [14] PADCONFIG149_ST_EN rw — Receiver Schmitt Trigger enable 0 - Schmitt trigger input disabled 1 - Schmitt trigger input enabled
  [13:11] PADCONFIG149_DEBOUNCE_SEL rw — Selects the debouce period for the pad.
  [8] PADCONFIG149_WK_LVL_POL rw — Level Sensitive Wakeup Polarity This bit is not relevant unless wk_lvl_en is set to 1'b1. 0 - Low. A low (0) value on the pin causes a wakeup 1 - High. A high (1) value on the pin causes a wakeup
  [7] PADCONFIG149_WK_LVL_EN rw — Level Sensitive Wakeup Enable 0 - Disabled. Wakeup is triggered by change of the pin input value 1 - Enabled. Wakeup is triggered when the pin matches the value specified by wk_lvl_pol. The chosen polarity must be maintained. (e.g. until wakeup completion is confirmed)
  [3:0] PADCONFIG149_MUXMODE rw — Pad functional signal mux selection Field values (others are reserved): 4'b0000 - Mux Mode 0 4'b0001 - Mux Mode 1 4'b0010 - Mux Mode 2 4'b0011 - Mux Mode 3 4'b0100 - Mux Mode 4 4'b0101 - Mux Mode 5 4'b0110 - Mux Mode 6 4'b0111 - Mux Mode 7 4'b1000 - Mux Mode 8 4'b1001 - Mux Mode 9 4'b1010 - Mux Mode 10 4'b1011 - Mux Mode 11 4'b1100 - Mux Mode 12 4'b1101 - Mux Mode 13 4'b1110 - Mux Mode 14 4'b1111 - Mux Mode 15
